AUTOSAR XML (schema 00051)
package /Components
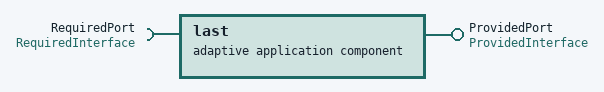
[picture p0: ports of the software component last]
  adaptive application sw component type last
    require port RequiredPort: queued-receiver-com-spec=data-element=In1, required-interface=RequiredInterface
    provide port ProvidedPort: queued-sender-com-spec=data-element=Out1, provided-interface=ProvidedInterface
